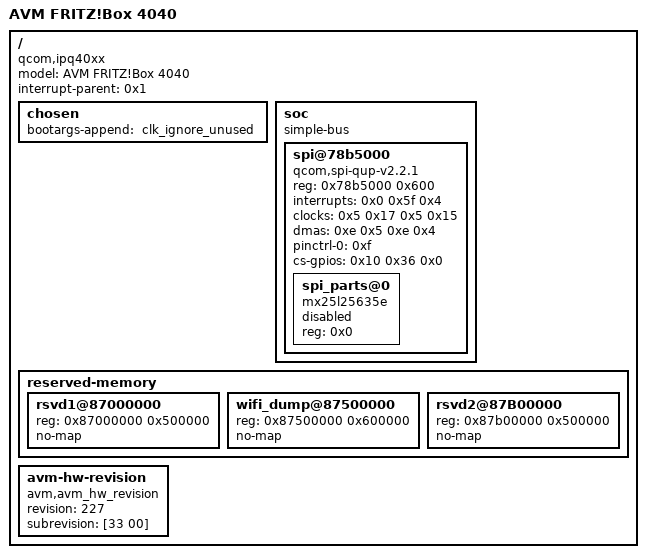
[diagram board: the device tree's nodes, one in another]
/dts-v1/;

/ {
	#address-cells = <0x1>;
	#size-cells = <0x1>;
	model = "AVM FRITZ!Box 4040";
	compatible = "qcom,ipq40xx";
	interrupt-parent = <0x1>;

	chosen {
		bootargs-append = " clk_ignore_unused ";
	};

	soc {
		#address-cells = <0x1>;
		#size-cells = <0x1>;
		ranges;
		compatible = "simple-bus";

		spi@78b5000 {
			compatible = "qcom,spi-qup-v2.2.1";
			reg = <0x78b5000 0x600>;
			interrupts = <0x0 0x5f 0x4>;
			clocks = <0x5 0x17 0x5 0x15>;
			clock-names = "core", "iface";
			#address-cells = <0x1>;
			#size-cells = <0x0>;
			dmas = <0xe 0x5 0xe 0x4>;
			dma-names = "rx", "tx";
			status = "ok";
			pinctrl-0 = <0xf>;
			pinctrl-names = "default";
			cs-gpios = <0x10 0x36 0x0>;

			spi_parts@0 {
				#address-cells = <0x1>;
				#size-cells = <0x1>;
				compatible = "mx25l25635e";
				reg = <0x0>;
				status = "disabled";
			};
		};
	};

	reserved-memory {
		#address-cells = <0x1>;
		#size-cells = <0x1>;
		ranges;

		rsvd1@87000000 {
			reg = <0x87000000 0x500000>;
			no-map;
		};

		wifi_dump@87500000 {
			reg = <0x87500000 0x600000>;
			no-map;
		};

		rsvd2@87B00000 {
			reg = <0x87b00000 0x500000>;
			no-map;
		};
	};

	avm-hw-revision {
		compatible = "avm,avm_hw_revision";
		revision = "227";
		subrevision = [33 00];
	};
};
